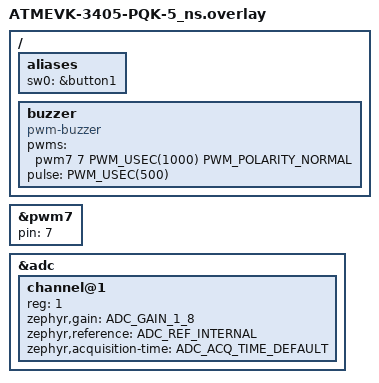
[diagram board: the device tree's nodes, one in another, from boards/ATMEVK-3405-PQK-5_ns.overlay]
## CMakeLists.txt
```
# Copyright (c) 2025 Atmosic
#
# SPDX-License-Identifier: Apache-2.0

cmake_minimum_required(VERSION 3.20.0)

find_package(Zephyr REQUIRED HINTS $ENV{ZEPHYR_BASE})
project(fp_tag)

target_sources(app PRIVATE
  src/main.c
)

add_subdirectory(src/platform)
```

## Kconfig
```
# Copyright (c) 2025 Atmosic
#
# SPDX-License-Identifier: Apache-2.0

source "Kconfig.zephyr"

module = FP_TAG
module-str = fp_tag
source "subsys/logging/Kconfig.template.log_config"
```

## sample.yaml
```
sample:
  description: Google Find My Device Network Tag
  name: Google Find My Device Network Tag
common:
  sysbuild: true
  harness: console
  harness_config:
    type: one_line
    regex:
      - "Press button to start pairing"
tests:
  applications.fp_tag.atm:
    tags: fp_tag atm33 atm34 no_mcuboot
    extra_args:
      - SB_CONFIG_SPE=y
  applications.fp_tag.atm.mcuboot:
    tags: fp_tag atm33 atm34 mcuboot
    extra_args:
      - SB_CONFIG_SPE=y
      - SB_CONFIG_BOOTLOADER_MCUBOOT=y
      - SB_CONFIG_BOOT_SIGNATURE_TYPE_ECDSA_P256=y
      - SB_CONFIG_MCUBOOT_MODE_SWAP_SCRATCH=y
      - SB_ATM_DTS_EXTRA_CPPFLAGS="-DDFU_IN_FLASH"
  applications.fp_tag.atm.mcuboot.ota:
    tags: fp_tag atm33 atm34 mcuboot
    extra_args:
      - SB_CONFIG_SPE=y
      - SB_CONFIG_BOOTLOADER_MCUBOOT=y
      - SB_CONFIG_BOOT_SIGNATURE_TYPE_ECDSA_P256=y
      - SB_CONFIG_MCUBOOT_MODE_SWAP_SCRATCH=y
      - SB_ATM_DTS_EXTRA_CPPFLAGS="-DDFU_IN_FLASH"
      - EXTRA_CONF_FILE="basic_ota_bt.conf"
  applications.fp_tag.atm.atmwstk.full:
    tags: fp_tag atm33 no_mcuboot
    extra_args:
      - SB_CONFIG_SPE=y
      - SB_ATM_DTS_EXTRA_CPPFLAGS="-DDFU_IN_FLASH"
      - SB_CONFIG_ATMWSTK_FULL=y
    extra_configs:
      - CONFIG_ATM_SOC_ALLOW="ATM33"
  applications.fp_tag.atm.mcuboot.atmwstk.full:
    tags: fp_tag atm33 mcuboot
    extra_args:
      - SB_CONFIG_SPE=y
      - SB_CONFIG_BOOTLOADER_MCUBOOT=y
      - SB_CONFIG_BOOT_SIGNATURE_TYPE_ECDSA_P256=y
      - SB_CONFIG_MCUBOOT_MODE_SWAP_SCRATCH=y
      - SB_CONFIG_ATMWSTK_FULL=y
      - SB_ATM_DTS_EXTRA_CPPFLAGS="-DDFU_IN_FLASH"
    extra_configs:
      - CONFIG_ATM_SOC_ALLOW="ATM33"
  applications.fp_tag.atm.atmwstk.cpd200:
    tags: fp_tag atm34 no_mcuboot
    extra_args:
      - SB_CONFIG_SPE=y
      - SB_CONFIG_ATMWSTK_CPD200=y
    extra_configs:
      - CONFIG_ATM_SOC_ALLOW="ATM34"
  applications.fp_tag.atm.mcuboot.atmwstk.cpd200:
    tags: fp_tag atm34 mcuboot
    extra_args:
      - SB_CONFIG_SPE=y
      - SB_CONFIG_BOOTLOADER_MCUBOOT=y
      - SB_CONFIG_BOOT_SIGNATURE_TYPE_ECDSA_P256=y
      - SB_CONFIG_MCUBOOT_MODE_SWAP_SCRATCH=y
      - SB_CONFIG_ATMWSTK_CPD200=y
    extra_configs:
      - CONFIG_ATM_SOC_ALLOW="ATM34"
  applications.fp_tag.atm.atmwstk.full.validator:
    tags: fp_tag atm33 no_mcuboot
    extra_args:
      - SB_CONFIG_SPE=y
      - SB_CONFIG_ATMWSTK_FULL=y
      - SB_ATM_DTS_EXTRA_CPPFLAGS="-DDFU_IN_FLASH"
    extra_configs:
      - CONFIG_FP_FMDN_VALIDATOR_TEST=y
      - CONFIG_BT_MAX_CONN=4
      - CONFIG_BT_EXT_ADV_MAX_ADV_SET=3
      - CONFIG_ATM_SOC_ALLOW="ATM33"
  applications.fp_tag.atm.atmwstk.cpd200.validator:
    tags: fp_tag atm34 no_mcuboot
    extra_args:
      - SB_CONFIG_SPE=y
      - SB_CONFIG_ATMWSTK_CPD200=y
    extra_configs:
      - CONFIG_FP_FMDN_VALIDATOR_TEST=y
      - CONFIG_BT_MAX_CONN=4
      - CONFIG_BT_EXT_ADV_MAX_ADV_SET=3
      - CONFIG_ATM_SOC_ALLOW="ATM34"
  applications.fp_tag.atm.mcuboot.serialdfu:
    tags: fp_tag atm33 atm34 no_mcuboot
    extra_args:
      - SB_CONFIG_SPE=y
      - SB_CONFIG_BOOTLOADER_MCUBOOT=y
      - SB_CONFIG_BOOT_SIGNATURE_TYPE_ECDSA_P256=y
      - SB_CONFIG_MCUBOOT_MODE_SWAP_SCRATCH=y
      - EXTRA_CONF_FILE="basic_ota_bt.conf;${ZEPHYR_OPENAIR_MODULE_DIR}/doc/dfu/overlay-serial-dfu.conf"
      - EXTRA_DTC_OVERLAY_FILE="${ZEPHYR_OPENAIR_MODULE_DIR}/applications/fp_tag/app_uart0.overlay"
      - SB_ATM_DTS_EXTRA_CPPFLAGS="-DDFU_IN_FLASH"
  applications.fp_tag.atm.mcuboot.flash_xip:
    tags: fp_tag atm34 mcuboot flash_xip
    extra_args:
      - SB_CONFIG_SPE=y
      - SB_CONFIG_BOOTLOADER_MCUBOOT=y
      - SB_CONFIG_BOOT_SIGNATURE_TYPE_ECDSA_P256=y
      - SB_CONFIG_ATMWSTK_PD50=y
      - SB_ATM_DTS_EXTRA_CPPFLAGS="-DRUN_IN_FLASH=2"
      - mcuboot_CONFIG_UPDATEABLE_IMAGE_NUMBER=2
    extra_configs:
      - CONFIG_ATM_SOC_ALLOW="ATM34"
  applications.fp_tag.atm.mcuboot.flash_xip.overwrite:
    tags: fp_tag atm34 mcuboot flash_xip overwrite
    extra_args:
      - SB_CONFIG_SPE=y
      - SB_CONFIG_BOOTLOADER_MCUBOOT=y
      - SB_CONFIG_BOOT_SIGNATURE_TYPE_ECDSA_P256=y
      - SB_CONFIG_MCUBOOT_MODE_OVERWRITE_ONLY=y
      - SB_CONFIG_ATMWSTK_PD50=y
      - SB_ATM_DTS_EXTRA_CPPFLAGS="-DATM_APP_FLASH_XIP;-DATM_MCUBOOT_SCRATCH_SIZE=0"
      - mcuboot_CONFIG_UPDATEABLE_IMAGE_NUMBER=2
      - mcuboot_CONFIG_MCUBOOT_VERIFY_IMG_ADDRESS=n
    extra_configs:
      - CONFIG_ATM_SOC_ALLOW="ATM34"
```

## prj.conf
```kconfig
# Let main thread priority lower than app work queue thread
CONFIG_MAIN_THREAD_PRIORITY=2
# # Increased stack for fp usage
CONFIG_SYSTEM_WORKQUEUE_STACK_SIZE=2048
CONFIG_MAIN_STACK_SIZE=2048

CONFIG_LOG=y
CONFIG_ASSERT=y

CONFIG_BT=y
CONFIG_BT_SMP=y
CONFIG_BT_PERIPHERAL=y
CONFIG_BT_DIS=y
CONFIG_BT_ATT_PREPARE_COUNT=5

CONFIG_BT_DEVICE_NAME="Atmosic Google Fast Pair demo tag"
CONFIG_BT_DEVICE_APPEARANCE=576
CONFIG_BT_SETTINGS=y
CONFIG_BT_BUF_EVT_DISCARDABLE_COUNT=1
CONFIG_BT_BUF_ACL_TX_COUNT=2
CONFIG_BT_BUF_EVT_RX_COUNT=3
CONFIG_BT_BUF_ACL_RX_SIZE=516
CONFIG_BT_ID_MAX=4
CONFIG_BT_EXT_ADV=y
CONFIG_BT_L2CAP_TX_MTU=512
CONFIG_BT_GATT_SERVICE_CHANGED=n
CONFIG_BT_GATT_ENFORCE_SUBSCRIPTION=n
CONFIG_BT_ATT_ERR_TO_STR=y

# flash
CONFIG_FLASH=y
CONFIG_FLASH_PAGE_LAYOUT=y
CONFIG_FLASH_MAP=y
CONFIG_NVS=y
CONFIG_SETTINGS=y
CONFIG_MPU_ALLOW_FLASH_WRITE=y

# battery
CONFIG_ADC=y
CONFIG_BATT_MODEL_COIN=y

# PWM buzzer
# CONFIG_ATM_BUZZER=y

# fp tag
CONFIG_ATM_GFP=y
CONFIG_MAX_TX_PWR=0
CONFIG_BT_MAX_CONN=3
CONFIG_BT_EXT_ADV_MAX_ADV_SET=2
CONFIG_PM=y

# Enable debug
# CONFIG_LOG_MODE_IMMEDIATE=y
# CONFIG_FP_TAG_LOG_LEVEL_DBG=y
# CONFIG_ATM_GFP_LOG_LEVEL_DBG=y
# CONFIG_ATM_GFPS_LOG_LEVEL_DBG=y
# CONFIG_ATM_DULT_LOG_LEVEL_DBG=y
```

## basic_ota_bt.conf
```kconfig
# Enable MCUmgr and dependencies.
CONFIG_ZCBOR=y
CONFIG_CRC=y
CONFIG_MCUMGR=y
CONFIG_STREAM_FLASH=y

# Enable most core commands.
CONFIG_IMG_MANAGER=y
CONFIG_MCUMGR_GRP_IMG=y
CONFIG_MCUMGR_GRP_OS=y

# Allow for large Bluetooth data packets.
CONFIG_BT_BUF_ACL_TX_SIZE=502

# Enable the Bluetooth mcumgr transport (unauthenticated).
CONFIG_MCUMGR_TRANSPORT_BT=y
CONFIG_MCUMGR_TRANSPORT_BT_CONN_PARAM_CONTROL=y
CONFIG_MCUMGR_TRANSPORT_BT_PERM_RW_ENCRYPT=y

# Enable the mcumgr Packet Reassembly feature over Bluetooth and its configuration dependencies.
# MCUmgr buffer size is optimized to fit one SMP packet divided into five Bluetooth Write Commands,
# transmitted with the maximum possible MTU value: 498 bytes.
CONFIG_MCUMGR_TRANSPORT_BT_REASSEMBLY=y
CONFIG_MCUMGR_TRANSPORT_NETBUF_SIZE=2475
CONFIG_MCUMGR_GRP_OS_MCUMGR_PARAMS=y
CONFIG_MCUMGR_TRANSPORT_WORKQUEUE_STACK_SIZE=4608

# Enable the storage erase command.
CONFIG_MCUMGR_GRP_ZBASIC=y
CONFIG_MCUMGR_GRP_ZBASIC_STORAGE_ERASE=y

# Disable Bluetooth ping support
CONFIG_BT_CTLR_LE_PING=n

# Enable logging
# CONFIG_MCUBOOT_UTIL_LOG_LEVEL_DBG=y
# CONFIG_MCUMGR_LOG_LEVEL_DBG=y
```

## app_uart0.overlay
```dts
/*
 * Copyright (c) 2025 Atmosic
 *
 * SPDX-License-Identifier: Apache-2.0
 */

&uart0 {
	status = "okay";
};
```

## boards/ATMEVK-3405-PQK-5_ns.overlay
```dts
/*
 * Copyright (c) 2025 Atmosic
 *
 * SPDX-License-Identifier: Apache-2.0
 */

/ {
	aliases {
		sw0 = &button1;
	};
	buzzer: buzzer {
		compatible = "pwm-buzzer";
		pwms = <&pwm7 7 PWM_USEC(1000) PWM_POLARITY_NORMAL>;
		pulse = <PWM_USEC(500)>;
	};
};

&pwm7 {
	pin = <7>;
	status = "okay";
};

&adc {
	#address-cells = <1>;
	#size-cells = <0>;

	channel@1 {
		reg = <1>;
		zephyr,gain = "ADC_GAIN_1_8";
		zephyr,reference = "ADC_REF_INTERNAL";
		zephyr,acquisition-time = <ADC_ACQ_TIME_DEFAULT>;
	};
};
```

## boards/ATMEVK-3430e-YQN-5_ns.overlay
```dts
/*
 * Copyright (c) 2025 Atmosic
 *
 * SPDX-License-Identifier: Apache-2.0
 */

/ {
	aliases {
		sw0 = &button1;
	};
	buzzer: buzzer {
		compatible = "atmosic,atm3x-pwm-buzzer";
		pwms = <&pwm3 3 PWM_USEC(1000) PWM_POLARITY_NORMAL>;
		pulse = <PWM_USEC(500)>;
	};
};

&pwm3 {
	pin = <29>;
	status = "okay";
};

&adc {
	#address-cells = <1>;
	#size-cells = <0>;

	channel@1 {
		reg = <1>;
		zephyr,gain = "ADC_GAIN_1_8";
		zephyr,reference = "ADC_REF_INTERNAL";
		zephyr,acquisition-time = <ADC_ACQ_TIME_DEFAULT>;
	};
};
```

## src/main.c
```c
/**
 *******************************************************************************
 *
 * @file main.c
 *
 * @brief Google Find My Device Network Tag application
 *
 * Copyright (C) Atmosic 2025
 *
 *******************************************************************************
 */

#include <errno.h>
#include <zephyr/kernel.h>
#include <zephyr/logging/log.h>
#include <zephyr/bluetooth/bluetooth.h>
#include <zephyr/settings/settings.h>
#include "fp_tag_platform.h"
#include "app_work_q.h"
#include "gfps.h"

LOG_MODULE_REGISTER(fp_tag, CONFIG_FP_TAG_LOG_LEVEL);

static void fp_tag_init_work_handler(struct k_work *work)
{
	fp_tag_platform_init();
}

K_WORK_DEFINE(fp_tag_init, fp_tag_init_work_handler);

static void fp_tag_bt_ready(void)
{
	if (!bt_is_ready()) {
		LOG_ERR("bt_is_ready is not ready");
	}

	// defer fp_tag_platform init to fp_work_q
	atm_work_submit_to_app_work_q(&fp_tag_init);
}

int main(void)
{

	fp_tag_platform_gpio_init();
	fp_tag_platform_reset_detect();

	int err = bt_enable(NULL);
	if (err) {
		LOG_WRN("Bluetooth enabled failed (err %d)", err);
		return 0;
	}
	LOG_INF("Bluetooth initialized");

	if (IS_ENABLED(CONFIG_SETTINGS)) {
		settings_load();
	}

	fp_tag_bt_ready();

	return 0;
}
```
